# MK61F15WS register map
File version: 1.6
Registers are 32-bit, read-write, reset 0x0 unless marked. A register's access mark holds for its fields unless they carry their own. Offsets are from the block's base; [hi:lo] are bit positions; 'fields as' and 'values as' point back to an identical list.

## MCM — Core Platform Miscellaneous Control Module
Base 0xE0080000; register names take the prefix MCM_
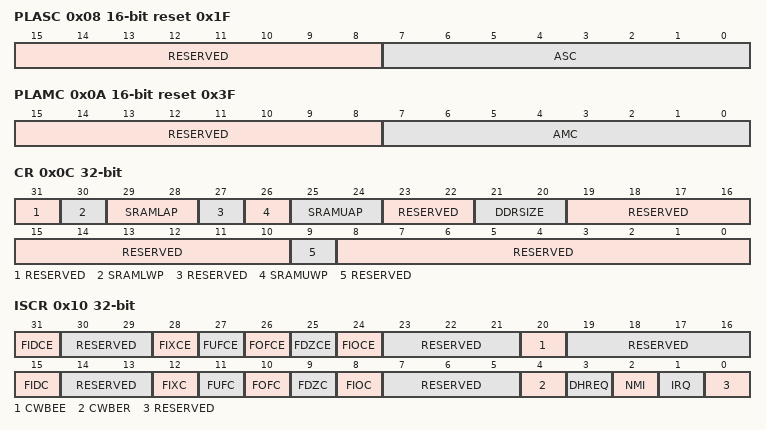
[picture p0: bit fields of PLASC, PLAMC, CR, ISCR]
0x08 PLASC 16-bit ro reset 0x1F — Crossbar Switch (AXBS) Slave Configuration
  [15:8] RESERVED
  [7:0] ASC — Each bit in the ASC field indicates whether there is a corresponding connection to the crossbar switch's slave input port.
    0=A bus slave connection to AXBS input port n is absent; 1=A bus slave connection to AXBS input port n is present
0x0A PLAMC 16-bit ro reset 0x3F — Crossbar Switch (AXBS) Master Configuration
  [15:8] RESERVED
  [7:0] AMC — Each bit in the AMC field indicates whether there is a corresponding connection to the AXBS master input port.
    0=A bus master connection to AXBS input port n is absent; 1=A bus master connection to AXBS input port n is present
0x0C CR — Control Register
  [31] RESERVED ro
  [30] SRAMLWP — SRAM_L Write Protect
  [29:28] SRAMLAP — SRAM_L arbitration priority
    0=Round robin; 1=Special round robin (favors SRAM backoor accesses over the processor); 2=Fixed priority. Processor has highest, backdoor has lowest; 3=Fixed priority. Backdoor has highest, processor has lowest
  [27] RESERVED ro
  [26] SRAMUWP — SRAM_U write protect
  [25:24] SRAMUAP — SRAM_U arbitration priority
    values as SRAMLAP
  [23:22] RESERVED ro
  [21:20] DDRSIZE — DDR address size translation
    0=DDR address translation is disabled; 1=DDR size is 128 Mbytes; 2=DDR size is 256 Mbytes; 3=DDR size is 512 Mbytes
  [19:10] RESERVED ro
  [9] RESERVED ro
  [8:0] RESERVED ro
0x10 ISCR — Interrupt Status and control Register
  [31] FIDCE — FPU input denormal interrupt enable
    0=Disable interrupt; 1=Enable interrupt
  [30:29] RESERVED ro
  [28] FIXCE — FPU inexact interrupt enable
    0=Disable interrupt; 1=Enable interrupt
  [27] FUFCE — FPU underflow interrupt enable
    0=Disable interrupt; 1=Enable interrupt
  [26] FOFCE — FPU overflow interrupt enable
    0=Disable interrupt; 1=Enable interrupt
  [25] FDZCE — FPU divide-by-zero interrupt enable
    0=Disable interrupt; 1=Enable interrupt
  [24] FIOCE — FPU invalid operation interrupt enable
    0=Disable interrupt; 1=Enable interrupt
  [23:21] RESERVED ro
  [20] CWBEE — Cache write buffer error enable
    0=Disable error interrupt; 1=Enable error interrupt
  [19:16] RESERVED ro
  [15] FIDC ro — FPU input denormal interrupt status
    0=No interrupt; 1=Interrupt occurred
  [14:13] RESERVED ro
  [12] FIXC ro — FPU inexact interrupt status
    0=No interrupt; 1=Interrupt occurred
  [11] FUFC ro — FPU underflow interrupt status
    0=No interrupt; 1=Interrupt occurred
  [10] FOFC ro — FPU overflow interrupt status
    0=No interrupt; 1=Interrupt occurred
  [9] FDZC ro — FPU divide-by-zero interrupt status
    0=No interrupt; 1=Interrupt occurred
  [8] FIOC ro — FPU invalid operation interrupt status
    0=No interrupt; 1=Interrupt occurred
  [7:5] RESERVED ro
  [4] CWBER — Cache write buffer error status
    0=No error; 1=Error occurred
  [3] DHREQ ro — Debug Halt Request Indicator
    0=No debug halt request; 1=Debug halt request initiated
  [2] NMI — Nonmaskable Interrupt Pending
    0=No pending NMI; 1=Due to the ETB counter expiring, an NMI is pending
  [1] IRQ — Normal Interrupt Pending
    0=No pending interrupt; 1=Due to the ETB counter expiring, a normal interrupt is pending
  [0] RESERVED ro
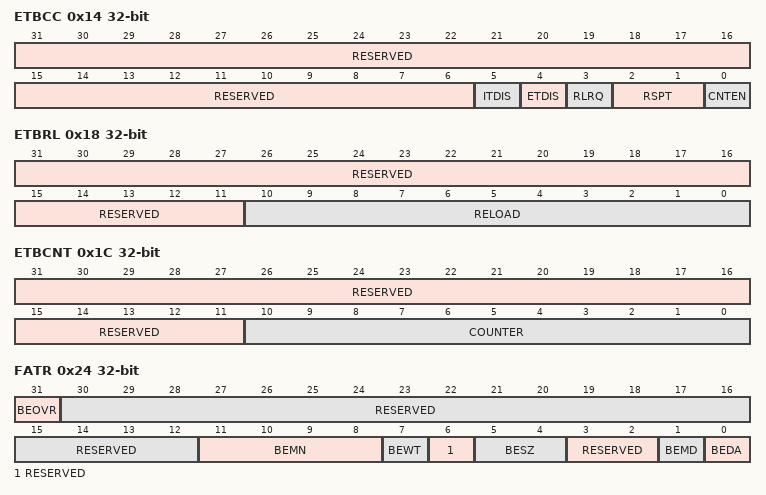
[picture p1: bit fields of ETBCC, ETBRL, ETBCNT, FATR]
0x14 ETBCC — ETB Counter Control register
  [31:6] RESERVED ro
  [5] ITDIS — ITM-To-TPIU Disable
    0=ITM-to-TPIU trace path enabled; 1=ITM-to-TPIU trace path disabled
  [4] ETDIS — ETM-To-TPIU Disable
    0=ETM-to-TPIU trace path enabled; 1=ETM-to-TPIU trace path disabled
  [3] RLRQ — Reload Request
    0=No effect; 1=Clears pending debug halt, NMI, or IRQ interrupt requests
  [2:1] RSPT — Response Type
    0=No response when the ETB count expires; 1=Generate a normal interrupt when the ETB count expires; 2=Generate an NMI when the ETB count expires; 3=Generate a debug halt when the ETB count expires
  [0] CNTEN — Counter Enable
    0=ETB counter disabled; 1=ETB counter enabled
0x18 ETBRL — ETB Reload register
  [31:11] RESERVED ro
  [10:0] RELOAD — Byte Count Reload Value
0x1C ETBCNT ro — ETB Counter Value register
  [31:11] RESERVED
  [10:0] COUNTER — Byte Count Counter Value
0x20 FADR ro reset not defined — Fault address register
  [31:0] ADDRESS — Fault address
0x24 FATR ro reset not defined — Fault attributes register
  [31] BEOVR — Bus error overrun
    0=No bus error overrun; 1=Bus error overrun occurred. The FADR and FDR registers and the other FATR bits are not updated to reflect this new bus error.
  [30:12] RESERVED
  [11:8] BEMN — Bus error master number
  [7] BEWT — Bus error write
    0=Read access; 1=Write access
  [6] RESERVED
  [5:4] BESZ — Bus error size
    0=8-bit access; 1=16-bit access; 2=32-bit access
  [3:2] RESERVED
  [1] BEMD — Bus error privilege level
    0=User mode; 1=Supervisor/privileged mode
  [0] BEDA — Bus error access type
    0=Instruction; 1=Data
0x28 FDR ro reset not defined — Fault data register
  [31:0] DATA — Fault data
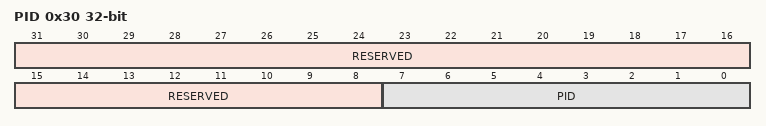
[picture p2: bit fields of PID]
0x30 PID — Process ID register
  [31:8] RESERVED ro
  [7:0] PID — M0_PID and M1_PID for MPU
